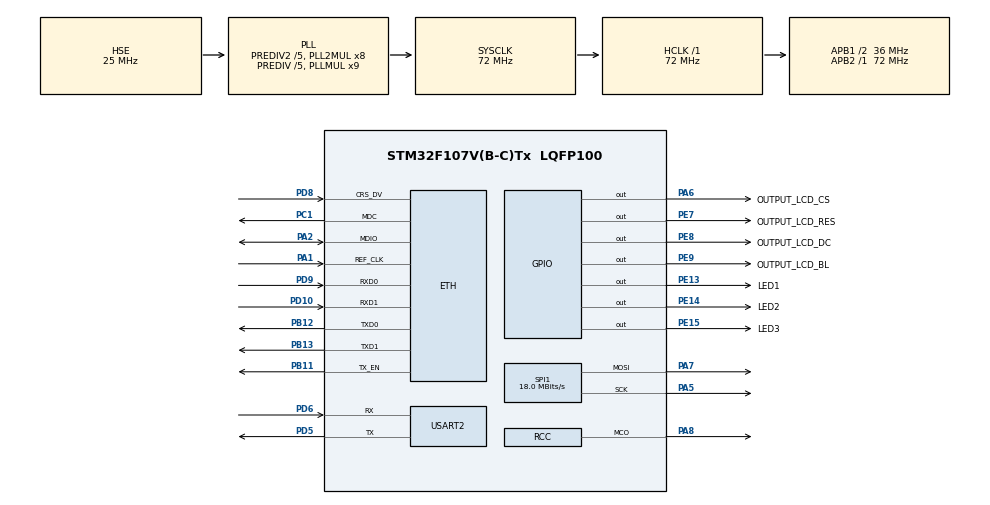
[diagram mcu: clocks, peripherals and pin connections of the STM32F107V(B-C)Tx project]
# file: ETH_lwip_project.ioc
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Dma.Request0=SPI1_TX
Dma.SPI1_TX.0.Direction=DMA_MEMORY_TO_PERIPH
Dma.SPI1_TX.0.Instance=DMA1_Channel3
Dma.SPI1_TX.0.MemDataAlignment=DMA_MDATAALIGN_BYTE
Dma.SPI1_TX.0.MemInc=DMA_MINC_ENABLE
Dma.SPI1_TX.0.Mode=DMA_NORMAL
Dma.SPI1_TX.0.PeriphDataAlignment=DMA_PDATAALIGN_BYTE
Dma.SPI1_TX.0.PeriphInc=DMA_PINC_DISABLE
Dma.SPI1_TX.0.Priority=DMA_PRIORITY_LOW
ETH.MediaInterface=ETH_MEDIA_INTERFACE_RMII
LWIP.GATEWAY_ADDRESS=192.168.001.001
LWIP.IP_ADDRESS=192.168.001.252
LWIP.LWIP_DHCP=1
LWIP.LWIP_NETIF_LINK_CALLBACK=1
LWIP.NETMASK_ADDRESS=255.255.255.000
LWIP.Version=v2.0.0_Cube
Mcu.Family=STM32F1
Mcu.Name=STM32F107V(B-C)Tx
Mcu.Package=LQFP100
NVIC.DMA1_Channel3_IRQn=true\:0\:0\:false\:false\:true\:false
NVIC.ETH_IRQn=true\:0\:0\:false\:false\:true\:true
NVIC.PriorityGroup=NVIC_PRIORITYGROUP_4
NVIC.TIM2_IRQn=true\:0\:0\:false\:false\:true\:true
OSC_IN.Mode=HSE-External-Oscillator
OSC_IN.Signal=RCC_OSC_IN
OSC_OUT.Mode=HSE-External-Oscillator
OSC_OUT.Signal=RCC_OSC_OUT
PA1.Mode=RMII
PA1.Signal=ETH_REF_CLK
PA13.Mode=Serial_Wire
PA13.Signal=SYS_JTMS-SWDIO
PA14.Mode=Serial_Wire
PA14.Signal=SYS_JTCK-SWCLK
PA2.Mode=RMII
PA2.Signal=ETH_MDIO
PA5.Mode=TX_Only_Simplex_Unidirect_Master
PA5.Signal=SPI1_SCK
PA6.GPIO_Label=OUTPUT_LCD_CS
PA6.Signal=GPIO_Output
PA7.Mode=TX_Only_Simplex_Unidirect_Master
PA7.Signal=SPI1_MOSI
PA8.GPIO_Speed=GPIO_SPEED_FREQ_HIGH
PA8.Mode=Clock-out
PA8.Signal=RCC_MCO
PB11.Mode=RMII
PB11.Signal=ETH_TX_EN
PB12.Mode=RMII
PB12.Signal=ETH_TXD0
PB13.Mode=RMII
PB13.Signal=ETH_TXD1
PC1.Mode=RMII
PC1.Signal=ETH_MDC
PD10.Mode=RMII
PD10.Signal=ETH_RXD1
PD5.Mode=Asynchronous
PD5.Signal=USART2_TX
PD6.Mode=Asynchronous
PD6.Signal=USART2_RX
PD8.Mode=RMII
PD8.Signal=ETH_CRS_DV
PD9.Mode=RMII
PD9.Signal=ETH_RXD0
PE13.GPIO_Label=LED1
PE13.PinState=GPIO_PIN_SET
PE13.Signal=GPIO_Output
PE14.GPIO_Label=LED2
PE14.PinState=GPIO_PIN_SET
PE14.Signal=GPIO_Output
PE15.GPIO_Label=LED3
PE15.PinState=GPIO_PIN_SET
PE15.Signal=GPIO_Output
PE7.GPIO_Label=OUTPUT_LCD_RES
PE7.Signal=GPIO_Output
PE8.GPIO_Label=OUTPUT_LCD_DC
PE8.Signal=GPIO_Output
PE9.GPIO_Label=OUTPUT_LCD_BL
PE9.Signal=GPIO_Output
ProjectManager.HeapSize=0x200
ProjectManager.StackSize=0x400
ProjectManager.TargetToolchain=MDK-ARM V5
RCC.AHBFreq_Value=72000000
RCC.APB1CLKDivider=RCC_HCLK_DIV2
RCC.APB1Freq_Value=36000000
RCC.APB1TimFreq_Value=72000000
RCC.APB2Freq_Value=72000000
RCC.APB2TimFreq_Value=72000000
RCC.HCLKFreq_Value=72000000
RCC.HSEDivPLL=RCC_HSE_PREDIV_DIV5
RCC.HSE_VALUE=25000000
RCC.PLL3Mul=RCC_PLLI2S_MUL10
RCC.PLLMUL=RCC_PLL_MUL9
RCC.PLLSourceVirtual=RCC_PLLSOURCE_HSE
RCC.Prediv1Source=RCC_PREDIV1_SOURCE_PLL2
RCC.Prediv2=RCC_HSE_PREDIV2_DIV5
RCC.RCC_MCOSource=RCC_MCO1SOURCE_PLL3CLK
RCC.SYSCLKFreq_VALUE=72000000
RCC.SYSCLKSource=RCC_SYSCLKSOURCE_PLLCLK
RCC.USBFreq_Value=48000000
SPI1.BaudRatePrescaler=SPI_BAUDRATEPRESCALER_4
SPI1.CalculateBaudRate=18.0 MBits/s
SPI1.Direction=SPI_DIRECTION_2LINES
SPI1.Mode=SPI_MODE_MASTER
SPI1.VirtualType=VM_MASTER
TIM2.Period=49999
TIM2.Prescaler=7199
USART2.VirtualMode=VM_ASYNC
VP_LWIP_VS_Enabled.Mode=Enabled
VP_TIM2_VS_ClockSourceINT.Mode=Internal
board=ETH_lwip_project

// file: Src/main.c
/**
  ******************************************************************************
  * File Name          : main.c
  * Description        : Main program body
  ******************************************************************************
  * This notice applies to any and all portions of this file
  * that are not between comment pairs USER CODE BEGIN and
  * USER CODE END. Other portions of this file, whether
  * inserted by the user or by software development tools
  * are owned by their respective copyright owners.
  *
  * Copyright (c) 2018 STMicroelectronics International N.V.
  * All rights reserved.
  *
  * Redistribution and use in source and binary forms, with or without
  * modification, are permitted, provided that the following conditions are met:
  *
  * 1. Redistribution of source code must retain the above copyright notice,
  *    this list of conditions and the following disclaimer.
  * 2. Redistributions in binary form must reproduce the above copyright notice,
  *    this list of conditions and the following disclaimer in the documentation
  *    and/or other materials provided with the distribution.
  * 3. Neither the name of STMicroelectronics nor the names of other
  *    contributors to this software may be used to endorse or promote products
  *    derived from this software without specific written permission.
  * 4. This software, including modifications and/or derivative works of this
  *    software, must execute solely and exclusively on microcontroller or
  *    microprocessor devices manufactured by or for STMicroelectronics.
  * 5. Redistribution and use of this software other than as permitted under
  *    this license is void and will automatically terminate your rights under
  *    this license.
  *
  * THIS SOFTWARE IS PROVIDED BY STMICROELECTRONICS AND CONTRIBUTORS "AS IS"
  * AND ANY EXPRESS, IMPLIED OR STATUTORY WARRANTIES, INCLUDING, BUT NOT
  * LIMITED TO, THE IMPLIED WARRANTIES OF MERCHANTABILITY, FITNESS FOR A
  * PARTICULAR PURPOSE AND NON-INFRINGEMENT OF THIRD PARTY INTELLECTUAL PROPERTY
  * RIGHTS ARE DISCLAIMED TO THE FULLEST EXTENT PERMITTED BY LAW. IN NO EVENT
  * SHALL STMICROELECTRONICS OR CONTRIBUTORS BE LIABLE FOR ANY DIRECT, INDIRECT,
  * INCIDENTAL, SPECIAL, EXEMPLARY, OR CONSEQUENTIAL DAMAGES (INCLUDING, BUT NOT
  * LIMITED TO, PROCUREMENT OF SUBSTITUTE GOODS OR SERVICES; LOSS OF USE, DATA,
  * OR PROFITS; OR BUSINESS INTERRUPTION) HOWEVER CAUSED AND ON ANY THEORY OF
  * LIABILITY, WHETHER IN CONTRACT, STRICT LIABILITY, OR TORT (INCLUDING
  * NEGLIGENCE OR OTHERWISE) ARISING IN ANY WAY OUT OF THE USE OF THIS SOFTWARE,
  * EVEN IF ADVISED OF THE POSSIBILITY OF SUCH DAMAGE.
  *
  ******************************************************************************
  */

#include "main.h"
#include "stm32f1xx_hal.h"
#include "lwip.h"

/* USER CODE BEGIN Includes */
#include "udp_echoclient.h"
#include "app_ethernet.h"
#include "user_timer.h"
#include  "spi_lcd.h"
#include "user_spi.h"
/* USER CODE END Includes */

SPI_HandleTypeDef hspi1;
DMA_HandleTypeDef hdma_spi1_tx;

TIM_HandleTypeDef htim2;

UART_HandleTypeDef huart2;

/* USER CODE BEGIN PV */
/* Private variables ---------------------------------------------------------*/
/* USER CODE END PV */

void SystemClock_Config(void);
static void MX_GPIO_Init(void);
static void MX_DMA_Init(void);
static void MX_USART2_UART_Init(void);
static void MX_TIM2_Init(void);
static void MX_SPI1_Init(void);

/* USER CODE BEGIN PFP */
/* Private function prototypes -----------------------------------------------*/

/* USER CODE END PFP */

int main(void)
{

  /* MCU Configuration----------------------------------------------------------*/

  /* Reset of all peripherals, Initializes the Flash interface and the Systick. */
  HAL_Init();

  /* Configure the system clock */
  SystemClock_Config();

  /* Initialize all configured peripherals */
  MX_GPIO_Init();
  MX_DMA_Init();
  MX_LWIP_Init();
  MX_USART2_UART_Init();
  MX_TIM2_Init();
  MX_SPI1_Init();

  /* USER CODE BEGIN 2 */
	user_timer_init();
	spi_lcd_init();
	user_spi_init();
  /* udp client connect */
  udp_echoclient_connect();

  /* Notify user about the netwoek interface config */
  User_notification(&gnetif);	     //用来检测网络有没有连通；
  /* USER CODE END 2 */

  /* Infinite loop */
  while (1)
  {

  /* USER CODE BEGIN 3 */
		MX_LWIP_Process();
  }
  /* USER CODE END 3 */

}

/** System Clock Configuration
*/
void SystemClock_Config(void)
{

  RCC_OscInitTypeDef RCC_OscInitStruct;
  RCC_ClkInitTypeDef RCC_ClkInitStruct;

    /**Initializes the CPU, AHB and APB busses clocks
    */
  RCC_OscInitStruct.OscillatorType = RCC_OSCILLATORTYPE_HSE;
  RCC_OscInitStruct.HSEState = RCC_HSE_ON;
  RCC_OscInitStruct.HSEPredivValue = RCC_HSE_PREDIV_DIV5;
  RCC_OscInitStruct.HSIState = RCC_HSI_ON;
  RCC_OscInitStruct.Prediv1Source = RCC_PREDIV1_SOURCE_PLL2;
  RCC_OscInitStruct.PLL.PLLState = RCC_PLL_ON;
  RCC_OscInitStruct.PLL.PLLSource = RCC_PLLSOURCE_HSE;
  RCC_OscInitStruct.PLL.PLLMUL = RCC_PLL_MUL9;
  RCC_OscInitStruct.PLL2.PLL2State = RCC_PLL2_ON;
  RCC_OscInitStruct.PLL2.PLL2MUL = RCC_PLL2_MUL8;
  RCC_OscInitStruct.PLL2.HSEPrediv2Value = RCC_HSE_PREDIV2_DIV5;
  if (HAL_RCC_OscConfig(&RCC_OscInitStruct) != HAL_OK)
  {
    _Error_Handler(__FILE__, __LINE__);
  }

    /**Initializes the CPU, AHB and APB busses clocks
    */
  RCC_ClkInitStruct.ClockType = RCC_CLOCKTYPE_HCLK|RCC_CLOCKTYPE_SYSCLK
                              |RCC_CLOCKTYPE_PCLK1|RCC_CLOCKTYPE_PCLK2;
  RCC_ClkInitStruct.SYSCLKSource = RCC_SYSCLKSOURCE_PLLCLK;
  RCC_ClkInitStruct.AHBCLKDivider = RCC_SYSCLK_DIV1;
  RCC_ClkInitStruct.APB1CLKDivider = RCC_HCLK_DIV2;
  RCC_ClkInitStruct.APB2CLKDivider = RCC_HCLK_DIV1;

  if (HAL_RCC_ClockConfig(&RCC_ClkInitStruct, FLASH_LATENCY_2) != HAL_OK)
  {
    _Error_Handler(__FILE__, __LINE__);
  }

  HAL_RCC_MCOConfig(RCC_MCO, RCC_MCO1SOURCE_PLL3CLK, RCC_MCODIV_1);

    /**Configure the Systick interrupt time
    */
  HAL_SYSTICK_Config(HAL_RCC_GetHCLKFreq()/1000);

    /**Configure the Systick
    */
  HAL_SYSTICK_CLKSourceConfig(SYSTICK_CLKSOURCE_HCLK);

    /**Configure the Systick interrupt time
    */
  __HAL_RCC_HSE_PREDIV2_CONFIG(RCC_HSE_PREDIV2_DIV5);

    /**Configure the Systick interrupt time
    */
  __HAL_RCC_PLLI2S_CONFIG(RCC_PLLI2S_MUL10);

    /**Configure the Systick interrupt time
    */
  __HAL_RCC_PLLI2S_ENABLE();

  /* SysTick_IRQn interrupt configuration */
  HAL_NVIC_SetPriority(SysTick_IRQn, 0, 0);
}

/* SPI1 init function */
static void MX_SPI1_Init(void)
{

  /* SPI1 parameter configuration*/
  hspi1.Instance = SPI1;
  hspi1.Init.Mode = SPI_MODE_MASTER;
  hspi1.Init.Direction = SPI_DIRECTION_2LINES;
  hspi1.Init.DataSize = SPI_DATASIZE_8BIT;
  hspi1.Init.CLKPolarity = SPI_POLARITY_LOW;
  hspi1.Init.CLKPhase = SPI_PHASE_1EDGE;
  hspi1.Init.NSS = SPI_NSS_SOFT;
  hspi1.Init.BaudRatePrescaler = SPI_BAUDRATEPRESCALER_4;
  hspi1.Init.FirstBit = SPI_FIRSTBIT_MSB;
  hspi1.Init.TIMode = SPI_TIMODE_DISABLE;
  hspi1.Init.CRCCalculation = SPI_CRCCALCULATION_DISABLE;
  hspi1.Init.CRCPolynomial = 10;
  if (HAL_SPI_Init(&hspi1) != HAL_OK)
  {
    _Error_Handler(__FILE__, __LINE__);
  }

}

/* TIM2 init function */
static void MX_TIM2_Init(void)
{

  TIM_ClockConfigTypeDef sClockSourceConfig;
  TIM_MasterConfigTypeDef sMasterConfig;

  htim2.Instance = TIM2;
  htim2.Init.Prescaler = 7199;
  htim2.Init.CounterMode = TIM_COUNTERMODE_UP;
  htim2.Init.Period = 49999;
  htim2.Init.ClockDivision = TIM_CLOCKDIVISION_DIV1;
  htim2.Init.AutoReloadPreload = TIM_AUTORELOAD_PRELOAD_DISABLE;
  if (HAL_TIM_Base_Init(&htim2) != HAL_OK)
  {
    _Error_Handler(__FILE__, __LINE__);
  }

  sClockSourceConfig.ClockSource = TIM_CLOCKSOURCE_INTERNAL;
  if (HAL_TIM_ConfigClockSource(&htim2, &sClockSourceConfig) != HAL_OK)
  {
    _Error_Handler(__FILE__, __LINE__);
  }

  sMasterConfig.MasterOutputTrigger = TIM_TRGO_RESET;
  sMasterConfig.MasterSlaveMode = TIM_MASTERSLAVEMODE_DISABLE;
  if (HAL_TIMEx_MasterConfigSynchronization(&htim2, &sMasterConfig) != HAL_OK)
  {
    _Error_Handler(__FILE__, __LINE__);
  }

}

/* USART2 init function */
static void MX_USART2_UART_Init(void)
{

  huart2.Instance = USART2;
  huart2.Init.BaudRate = 115200;
  huart2.Init.WordLength = UART_WORDLENGTH_8B;
  huart2.Init.StopBits = UART_STOPBITS_1;
  huart2.Init.Parity = UART_PARITY_NONE;
  huart2.Init.Mode = UART_MODE_TX_RX;
  huart2.Init.HwFlowCtl = UART_HWCONTROL_NONE;
  huart2.Init.OverSampling = UART_OVERSAMPLING_16;
  if (HAL_UART_Init(&huart2) != HAL_OK)
  {
    _Error_Handler(__FILE__, __LINE__);
  }

}

static void MX_DMA_Init(void)
{
  /* DMA controller clock enable */
  __HAL_RCC_DMA1_CLK_ENABLE();

  /* DMA interrupt init */
  /* DMA1_Channel3_IRQn interrupt configuration */
  HAL_NVIC_SetPriority(DMA1_Channel3_IRQn, 0, 0);
  HAL_NVIC_EnableIRQ(DMA1_Channel3_IRQn);

}

/** Configure pins as
        * Analog
        * Input
        * Output
        * EVENT_OUT
        * EXTI
     PA8   ------> RCC_MCO
*/
static void MX_GPIO_Init(void)
{

  GPIO_InitTypeDef GPIO_InitStruct;

  /* GPIO Ports Clock Enable */
  __HAL_RCC_GPIOC_CLK_ENABLE();
  __HAL_RCC_GPIOA_CLK_ENABLE();
  __HAL_RCC_GPIOE_CLK_ENABLE();
  __HAL_RCC_GPIOB_CLK_ENABLE();
  __HAL_RCC_GPIOD_CLK_ENABLE();

  /*Configure GPIO pin Output Level */
  HAL_GPIO_WritePin(OUTPUT_LCD_CS_GPIO_Port, OUTPUT_LCD_CS_Pin, GPIO_PIN_RESET);

  /*Configure GPIO pin Output Level */
  HAL_GPIO_WritePin(GPIOE, OUTPUT_LCD_RES_Pin|OUTPUT_LCD_DC_Pin|OUTPUT_LCD_BL_Pin, GPIO_PIN_RESET);

  /*Configure GPIO pin Output Level */
  HAL_GPIO_WritePin(GPIOE, LED1_Pin|LED2_Pin|LED3_Pin, GPIO_PIN_SET);

  /*Configure GPIO pin : OUTPUT_LCD_CS_Pin */
  GPIO_InitStruct.Pin = OUTPUT_LCD_CS_Pin;
  GPIO_InitStruct.Mode = GPIO_MODE_OUTPUT_PP;
  GPIO_InitStruct.Speed = GPIO_SPEED_FREQ_LOW;
  HAL_GPIO_Init(OUTPUT_LCD_CS_GPIO_Port, &GPIO_InitStruct);

  /*Configure GPIO pins : OUTPUT_LCD_RES_Pin OUTPUT_LCD_DC_Pin OUTPUT_LCD_BL_Pin LED1_Pin
                           LED2_Pin LED3_Pin */
  GPIO_InitStruct.Pin = OUTPUT_LCD_RES_Pin|OUTPUT_LCD_DC_Pin|OUTPUT_LCD_BL_Pin|LED1_Pin
                          |LED2_Pin|LED3_Pin;
  GPIO_InitStruct.Mode = GPIO_MODE_OUTPUT_PP;
  GPIO_InitStruct.Speed = GPIO_SPEED_FREQ_LOW;
  HAL_GPIO_Init(GPIOE, &GPIO_InitStruct);

  /*Configure GPIO pin : PA8 */
  GPIO_InitStruct.Pin = GPIO_PIN_8;
  GPIO_InitStruct.Mode = GPIO_MODE_AF_PP;
  GPIO_InitStruct.Speed = GPIO_SPEED_FREQ_HIGH;
  HAL_GPIO_Init(GPIOA, &GPIO_InitStruct);

}

void _Error_Handler(char * file, int line)
{
  while(1)
  {
  }
}

/************************ (C) COPYRIGHT STMicroelectronics *****END OF FILE****/
